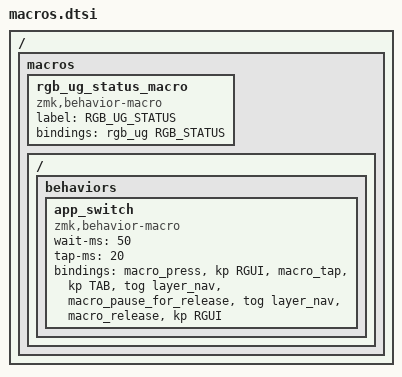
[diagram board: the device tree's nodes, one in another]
/ {
    macros {
        rgb_ug_status_macro: rgb_ug_status_macro {
            label = "RGB_UG_STATUS";
            compatible = "zmk,behavior-macro";
            #binding-cells = <0>;
            bindings = <&rgb_ug RGB_STATUS>;
        };

        ZMK_MACRO(app_switch,
            wait-ms = <50>;
            tap-ms = <20>;
            bindings =
                        <&macro_press &kp RGUI>
                      , <&macro_tap &kp TAB>
                      , <&tog layer_nav>
                      //, <&macro_wait_time 500>
                      , <&macro_pause_for_release>
                      , <&tog layer_nav>
                      , <&macro_release &kp RGUI>
                      ;
        )
    };
};
